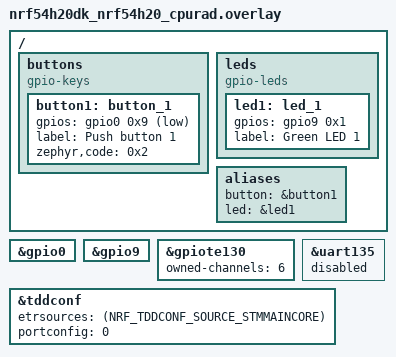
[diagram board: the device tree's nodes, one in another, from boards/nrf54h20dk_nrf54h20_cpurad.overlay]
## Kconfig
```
#
# Copyright (c) 2024 Nordic Semiconductor ASA
#
# SPDX-License-Identifier: LicenseRef-Nordic-5-Clause
#

menu "CoreMark sample"

config APP_MODE_FLASH_AND_RUN
	bool "Run CoreMark benchmark on start up" if \
		!(SOC_NRF54H20_CPUPPR)
	default y if SOC_NRF54H20_CPUPPR
	help
	  If enabled, CoreMark will start execution immediately after the CPU starts up.
	  It also disables LEDs and buttons.
	  Otherwise, it will wait for the button press.

endmenu

menu "Zephyr Kernel"
	source "Kconfig.zephyr"
endmenu
```

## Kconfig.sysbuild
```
#
# Copyright (c) 2024 Nordic Semiconductor ASA
#
# SPDX-License-Identifier: LicenseRef-Nordic-5-Clause
#

source "share/sysbuild/Kconfig"

config APP_CPUNET_RUN
	bool "Run the CoreMark benchmark on the network or radio core"
	depends on SUPPORT_NETCORE
	default y

config APP_CPUPPR_RUN
	bool "Run the CoreMark benchmark on the PPR core"
	depends on SUPPORT_PPRCORE
	default y
```

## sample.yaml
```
sample:
  name: CoreMark Benchmark
  description: CoreMark sample for the CPU performance evaluation.
               Sample runs the CoreMark benchmark that measures the CPU efficiency
               performing different algorithms like state machine, CRC calculation,
               matrix manipulation and list processing (find and sort).
tests:
  sample.benchmark.coremark:
    sysbuild: true
    build_only: true
    platform_allow:
      - nrf52840dk/nrf52840
      - nrf52833dk/nrf52833
      - nrf52dk/nrf52832
      - nrf5340dk/nrf5340/cpuapp
      - nrf54l15dk/nrf54l15/cpuapp
      - nrf54h20dk/nrf54h20/cpuapp
    integration_platforms:
      - nrf52840dk/nrf52840
      - nrf52833dk/nrf52833
      - nrf52dk/nrf52832
      - nrf5340dk/nrf5340/cpuapp
      - nrf54l15dk/nrf54l15/cpuapp
      - nrf54h20dk/nrf54h20/cpuapp
    tags: ci_build sysbuild ci_samples_benchmarks
  sample.benchmark.coremark.flash_and_run:
    sysbuild: true
    build_only: false
    platform_allow:
      - nrf52840dk/nrf52840
      - nrf52833dk/nrf52833
      - nrf52dk/nrf52832
      - nrf5340dk/nrf5340/cpuapp
      - nrf54l15dk/nrf54l15/cpuapp
      - nrf54h20dk/nrf54h20/cpuapp
    integration_platforms:
      - nrf52840dk/nrf52840
      - nrf52833dk/nrf52833
      - nrf52dk/nrf52832
      - nrf5340dk/nrf5340/cpuapp
      - nrf54l15dk/nrf54l15/cpuapp
      - nrf54h20dk/nrf54h20/cpuapp
    tags: ci_build sysbuild ci_samples_benchmarks
    harness: console
    harness_config:
      ordered: false
      regex:
        - "CoreMark started!"
        - "Correct operation validated."
      type: multi_line
    extra_args: FILE_SUFFIX=flash_and_run
  sample.benchmark.coremark.heap_memory:
    sysbuild: true
    build_only: true
    platform_allow:
      - nrf52840dk/nrf52840
      - nrf52833dk/nrf52833
      - nrf52dk/nrf52832
      - nrf5340dk/nrf5340/cpuapp
      - nrf54l15dk/nrf54l15/cpuapp
      - nrf54h20dk/nrf54h20/cpuapp
    integration_platforms:
      - nrf52840dk/nrf52840
      - nrf52833dk/nrf52833
      - nrf52dk/nrf52832
      - nrf5340dk/nrf5340/cpuapp
      - nrf54l15dk/nrf54l15/cpuapp
      - nrf54h20dk/nrf54h20/cpuapp
    tags: ci_build sysbuild ci_samples_benchmarks
    extra_args: FILE_SUFFIX=heap_memory
  sample.benchmark.coremark.static_memory:
    sysbuild: true
    build_only: true
    platform_allow:
      - nrf52840dk/nrf52840
      - nrf52833dk/nrf52833
      - nrf52dk/nrf52832
      - nrf5340dk/nrf5340/cpuapp
      - nrf54l15dk/nrf54l15/cpuapp
      - nrf54h20dk/nrf54h20/cpuapp
    integration_platforms:
      - nrf52840dk/nrf52840
      - nrf52833dk/nrf52833
      - nrf52dk/nrf52832
      - nrf5340dk/nrf5340/cpuapp
      - nrf54l15dk/nrf54l15/cpuapp
      - nrf54h20dk/nrf54h20/cpuapp
    tags: ci_build sysbuild ci_samples_benchmarks
    extra_args: FILE_SUFFIX=static_memory
  sample.benchmark.coremark.multiple_threads:
    sysbuild: true
    build_only: true
    platform_allow:
      - nrf52840dk/nrf52840
      - nrf52833dk/nrf52833
      - nrf52dk/nrf52832
      - nrf5340dk/nrf5340/cpuapp
      - nrf54l15dk/nrf54l15/cpuapp
      - nrf54h20dk/nrf54h20/cpuapp
    integration_platforms:
      - nrf52840dk/nrf52840
      - nrf52833dk/nrf52833
      - nrf52dk/nrf52832
      - nrf5340dk/nrf5340/cpuapp
      - nrf54l15dk/nrf54l15/cpuapp
      - nrf54h20dk/nrf54h20/cpuapp
    tags: ci_build sysbuild ci_samples_benchmarks
    extra_args: FILE_SUFFIX=multiple_threads
```

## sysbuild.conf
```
#
# Copyright (c) 2024 Nordic Semiconductor ASA
#
# SPDX-License-Identifier: LicenseRef-Nordic-5-Clause

SB_CONFIG_PARTITION_MANAGER=n
```

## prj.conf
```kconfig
#
# Copyright (c) 2024 Nordic Semiconductor ASA
#
# SPDX-License-Identifier: LicenseRef-Nordic-5-Clause

# Common coremark configuration
############################################################################
CONFIG_COREMARK=y

# Compiler options
CONFIG_COMPILER_OPT="-O3"

# Config results output
# The default logging level is set to the OFF level.
# Kernel error logging is enabled to notify the developer about system faults.
CONFIG_LOG=y
CONFIG_LOG_DEFAULT_LEVEL=0
CONFIG_KERNEL_LOG_LEVEL_ERR=y
CONFIG_CBPRINTF_FP_SUPPORT=y

CONFIG_GPIO=y

CONFIG_MAIN_THREAD_PRIORITY=-1

# Configuration variant:
# Memory allocation using the stack memory
# Single-threaded benchmark execution
# Benchmark execution on a button press
############################################################################

# Increse if number of threads increases.
CONFIG_MAIN_STACK_SIZE=4096
```

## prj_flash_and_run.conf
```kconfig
#
# Copyright (c) 2024 Nordic Semiconductor ASA
#
# SPDX-License-Identifier: LicenseRef-Nordic-5-Clause

# Common coremark configuration
############################################################################
CONFIG_COREMARK=y

# Compiler options
CONFIG_COMPILER_OPT="-O3"

# Config results output
# The default logging level is set to the OFF level.
# Kernel error logging is enabled to notify the developer about system faults.
CONFIG_LOG=y
CONFIG_LOG_DEFAULT_LEVEL=0
CONFIG_KERNEL_LOG_LEVEL_ERR=y
CONFIG_CBPRINTF_FP_SUPPORT=y

CONFIG_GPIO=y

CONFIG_MAIN_THREAD_PRIORITY=-1

# Configuration variant:
# Memory allocation using the stack memory
# Single-threaded benchmark execution
# Benchmark execution automatic after boot
############################################################################
CONFIG_APP_MODE_FLASH_AND_RUN=y

# Increse if number of threads increases.
CONFIG_MAIN_STACK_SIZE=4096
```

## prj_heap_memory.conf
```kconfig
#
# Copyright (c) 2024 Nordic Semiconductor ASA
#
# SPDX-License-Identifier: LicenseRef-Nordic-5-Clause

# Common coremark configuration
############################################################################
CONFIG_COREMARK=y

# Compiler options
CONFIG_COMPILER_OPT="-O3"

# Config results output
# The default logging level is set to the OFF level.
# Kernel error logging is enabled to notify the developer about system faults.
CONFIG_LOG=y
CONFIG_LOG_DEFAULT_LEVEL=0
CONFIG_KERNEL_LOG_LEVEL_ERR=y
CONFIG_CBPRINTF_FP_SUPPORT=y

CONFIG_GPIO=y

CONFIG_MAIN_THREAD_PRIORITY=-1

# Configuration variant:
# Memory allocation using the heap memory
# Single-threaded benchmark execution
# Benchmark execution on a button press
############################################################################

# Use heap memory allocation.
CONFIG_COREMARK_MEMORY_METHOD_MALLOC=y

# Adjust the heap memory size and main stack size.
# Increse if number of threads increases.
CONFIG_MAIN_STACK_SIZE=4096
CONFIG_HEAP_MEM_POOL_SIZE=4096
```

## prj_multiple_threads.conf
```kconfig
#
# Copyright (c) 2024 Nordic Semiconductor ASA
#
# SPDX-License-Identifier: LicenseRef-Nordic-5-Clause

# Common coremark configuration
############################################################################
CONFIG_COREMARK=y

# Compiler options
CONFIG_COMPILER_OPT="-O3"

# Config results output
# The default logging level is set to the OFF level.
# Kernel error logging is enabled to notify the developer about system faults.
CONFIG_LOG=y
CONFIG_LOG_DEFAULT_LEVEL=0
CONFIG_KERNEL_LOG_LEVEL_ERR=y
CONFIG_CBPRINTF_FP_SUPPORT=y

CONFIG_GPIO=y

CONFIG_MAIN_THREAD_PRIORITY=-1

# Configuration variant:
# Memory allocation using the stack memory
# Multi-threaded benchmark execution
# Benchmark execution on a button press
############################################################################

# Multi-threaded execution.
CONFIG_COREMARK_THREADS_NUMBER=4

# Increse if number of threads increases.
CONFIG_TIMESLICE_SIZE=10
CONFIG_MAIN_STACK_SIZE=10240
```

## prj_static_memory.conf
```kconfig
#
# Copyright (c) 2024 Nordic Semiconductor ASA
#
# SPDX-License-Identifier: LicenseRef-Nordic-5-Clause

# Common coremark configuration
############################################################################
CONFIG_COREMARK=y

# Compiler options
CONFIG_COMPILER_OPT="-O3"

# Config results output
# The default logging level is set to the OFF level.
# Kernel error logging is enabled to notify the developer about system faults.
CONFIG_LOG=y
CONFIG_LOG_DEFAULT_LEVEL=0
CONFIG_KERNEL_LOG_LEVEL_ERR=y
CONFIG_CBPRINTF_FP_SUPPORT=y

CONFIG_GPIO=y

CONFIG_MAIN_THREAD_PRIORITY=-1

# Configuration variant:
# Memory allocation using the static memory
# Single-threaded benchmark execution
# Benchmark execution on a button press
############################################################################

# Use static memory allocation.
CONFIG_COREMARK_MEMORY_METHOD_STATIC=y

# Increse if number of threads increases.
CONFIG_MAIN_STACK_SIZE=4096
```

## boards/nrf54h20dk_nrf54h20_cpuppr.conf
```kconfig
#
# Copyright (c) 2024 Nordic Semiconductor ASA
#
# SPDX-License-Identifier: LicenseRef-Nordic-5-Clause

CONFIG_COREMARK_ITERATIONS=500

# Disable the UART console Kconfig to make Kconfig configuration with the DTS configuration.
CONFIG_UART_CONSOLE=n

# Kconfigs required for the STM standalone logging, imported from the nordic-log-stm snippet.
CONFIG_TEST_LOGGING_DEFAULTS=n
CONFIG_LOG_FRONTEND=y
CONFIG_LOG_FRONTEND_ONLY=y
CONFIG_LOG_FRONTEND_STMESP=y
CONFIG_LOG_FRONTEND_STMESP_FSC=y

# Disable the NCS boot banner - the application core is responsible for printing the boot banner.
CONFIG_NCS_BOOT_BANNER=n
CONFIG_BOOT_BANNER=n
```

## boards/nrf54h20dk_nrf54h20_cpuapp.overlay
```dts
/*
 * Copyright (c) 2024 Nordic Semiconductor ASA
 *
 * SPDX-License-Identifier: LicenseRef-Nordic-5-Clause
 */

 #include "app_aliases_common.overlay"

/ {
	chosen {
		zephyr,sram = &cpuapp_ram0;
	};

	aliases {
		/delete-property/ led1;
		/delete-property/ sw1;
	};
};

/delete-node/ &button1;
/delete-node/ &led1;

&button0 {
	label = "Push button 0";
};

&gpiote130 {
	/* Select the only free channel. */
	owned-channels = <7>;
	status = "okay";
};

/* DTS nodes required to run the cpuppr target. */
&cpuppr_vpr {
	status = "okay";
};

&cpuppr_ram3x_region {
	status = "okay";
};

/* DTS nodes required for the STM standalone logging, imported from the nordic-log-stm snippet. */
&tbm {
	status = "okay";
};

&tddconf {
	status = "okay";
	etrsources = <(NRF_TDDCONF_SOURCE_STMMAINCORE | NRF_TDDCONF_SOURCE_STMPPR)>;
	portconfig = <0>;
};
```

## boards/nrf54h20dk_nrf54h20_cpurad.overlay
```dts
/*
 * Copyright (c) 2024 Nordic Semiconductor ASA
 *
 * SPDX-License-Identifier: LicenseRef-Nordic-5-Clause
 */

/ {
	buttons {
		compatible = "gpio-keys";
		button1: button_1 {
			gpios = < &gpio0 0x9 0x11 >;
			label = "Push button 1";
			zephyr,code = < 0x2 >;
		};
	};

	leds {
		compatible = "gpio-leds";
		led1: led_1 {
			gpios = < &gpio9 0x1 0x0 >;
			label = "Green LED 1";
		};
	};

	aliases {
		button = &button1;
		led = &led1;
	};
 };

&gpio0 {
	status = "okay";
};

&gpio9 {
	status = "okay";
};

&gpiote130 {
	owned-channels = <6>;
	status = "okay";
};

/* Disable the default UART node for the radio core, as logs are forwarded
 * with STM and the application core UART. This setting also prevents access
 * issues to the same UART instance from two or more different cores.
 */
&uart135 {
	status = "disabled";
};

/* DTS nodes required for the STM standalone logging, imported from the nordic-log-stm snippet. */
&tddconf {
	status = "okay";
	etrsources = <(NRF_TDDCONF_SOURCE_STMMAINCORE)>;
	portconfig = <0>;
};
```

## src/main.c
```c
/*
 * Copyright (c) 2024 Nordic Semiconductor ASA
 *
 * SPDX-License-Identifier: LicenseRef-Nordic-5-Clause
 */

#include <zephyr/init.h>
#include <zephyr/kernel.h>
#include <zephyr/logging/log.h>
#include <zephyr/drivers/gpio.h>
#include <zephyr/drivers/misc/coresight/nrf_etr.h>
#include <system_nrf.h>

#include "coremark_zephyr.h"

LOG_MODULE_REGISTER(app, LOG_LEVEL_INF);

#ifndef CONFIG_APP_MODE_FLASH_AND_RUN
/*
 * Get button configuration from the devicetree. This is mandatory.
 */
#define BUTTON_NODE             DT_ALIAS(button)
#define LED_NODE                DT_ALIAS(led)

#if !DT_NODE_HAS_STATUS(BUTTON_NODE, okay)
	#error "Unsupported board: /"button/" alias is not defined."
#endif

#if !DT_NODE_HAS_STATUS(LED_NODE, okay)
	#error "Unsupported board: /"led/" alias is not defined."
#endif

#define BUTTON_LABEL            DT_PROP(DT_ALIAS(button), label)
#define LED_ON()                (void)gpio_pin_set_dt(&status_led, 1)
#define LED_OFF()               (void)gpio_pin_set_dt(&status_led, 0)

static const struct gpio_dt_spec start_button = GPIO_DT_SPEC_GET(BUTTON_NODE, gpios);
static const struct gpio_dt_spec status_led = GPIO_DT_SPEC_GET(LED_NODE, gpios);

#else

#define BUTTON_LABEL            "Reset"
#define LED_ON()
#define LED_OFF()

static const struct gpio_dt_spec start_button;
static const struct gpio_dt_spec status_led;

#endif

static K_SEM_DEFINE(start_coremark, 0, 1);
static atomic_t coremark_in_progress;

static void logging_mode_multi_domain_blocked_state_indicate(void)
{
	if (!IS_ENABLED(CONFIG_NRF_ETR)) {
		return;
	}

	LOG_INF("Logging is blocked for all cores until this core finishes the CoreMark "
		"benchmark\n");

	/* The wait time is necessary to include the log in the ETR flush operation. The logging
	 * frontend submits the log to the STM port (STMESP), which STM processes and directs the
	 * generated logging stream to the STM sink - ETR. The log should be available in the ETR
	 * peripheral after the sleep operation.
	 */
	k_sleep(K_MSEC(100));

	/* Flush logs from the ETR and direct them to UART. */
	nrf_etr_flush();
}

static int logging_mode_indicate(void)
{
	/* Enforce synchronous logging as the sample doesn't flush logs. */
	BUILD_ASSERT(IS_ENABLED(CONFIG_LOG_MODE_MINIMAL) ||
		     IS_ENABLED(CONFIG_LOG_MODE_IMMEDIATE) ||
		     IS_ENABLED(CONFIG_LOG_FRONTEND_ONLY),
		     "Logs should be processed synchronously to avoid negative impact on the "
		     "benchamrk performance");

	/* Standard logging mode */
	if (IS_ENABLED(CONFIG_LOG_MODE_MINIMAL) || IS_ENABLED(CONFIG_LOG_MODE_IMMEDIATE)) {
		LOG_INF("Standard logging mode\n");

		return 0;
	}

	/* Multi-domain logging mode */
	if (IS_ENABLED(CONFIG_LOG_FRONTEND_ONLY) || IS_ENABLED(CONFIG_LOG_FRONTEND_STMESP)) {
		/* Only the core responsible for moving the logs from the STM sink to UART
		 * indicates the logging mode.
		 */
		if (IS_ENABLED(CONFIG_NRF_ETR)) {
			LOG_INF("Multi-domain logging mode");
			LOG_INF("This core is used to output logs from all cores to terminal "
				"over UART\n");
		}

		return 0;
	}

	/* This part should never be executed. */
	k_panic();

	return 0;
}

SYS_INIT(logging_mode_indicate, APPLICATION, CONFIG_APPLICATION_INIT_PRIORITY);

static void button_pressed(const struct device *dev, struct gpio_callback *cb, uint32_t pins)
{
	if (gpio_pin_get_dt(&start_button) && atomic_cas(&coremark_in_progress, false, true)) {
		LOG_INF("%s pressed!", BUTTON_LABEL);
		k_sem_give(&start_coremark);
	}
}

static int led_init(void)
{
	int ret;

	if (!device_is_ready(status_led.port)) {
		LOG_ERR("Error: led device %s is not ready",
			status_led.port->name);
		return -ENODEV;
	}

	ret = gpio_pin_configure_dt(&status_led, GPIO_OUTPUT);
	if (ret != 0) {
		LOG_ERR("Error %d: failed to configure %s pin %d",
			ret, status_led.port->name, status_led.pin);
		return ret;
	}

	LED_OFF();

	return ret;
}

static int button_init(void)
{
	int ret;
	static struct gpio_callback button_cb_data;

	if (!device_is_ready(start_button.port)) {
		LOG_ERR("Error: button1 device %s is not ready",
			start_button.port->name);
		return -ENODEV;
	}

	ret = gpio_pin_configure_dt(&start_button, GPIO_INPUT);
	if (ret != 0) {
		LOG_ERR("Error %d: failed to configure %s pin %d",
			ret, start_button.port->name, start_button.pin);
		return ret;
	}

	ret = gpio_pin_interrupt_configure_dt(&start_button, GPIO_INT_EDGE_TO_ACTIVE);
	if (ret != 0) {
		LOG_ERR("Error %d: failed to configure interrupt on %s pin %d",
			ret, start_button.port->name, start_button.pin);
		return ret;
	}

	(void) gpio_init_callback(&button_cb_data, button_pressed, BIT(start_button.pin));
	(void) gpio_add_callback(start_button.port, &button_cb_data);

	return ret;
}

int main(void)
{
	LOG_INF("CoreMark sample for %s", CONFIG_BOARD_TARGET);

	if (IS_ENABLED(CONFIG_APP_MODE_FLASH_AND_RUN)) {
		(void)atomic_set(&coremark_in_progress, true);
		k_sem_give(&start_coremark);
	} else if (!IS_ENABLED(CONFIG_APP_MODE_FLASH_AND_RUN)) {
		if (led_init()) {
			k_panic();
		}
		if (button_init()) {
			k_panic();
		}

		LOG_INF("Press %s to start the test ...\n",  BUTTON_LABEL);
	}

	while (true) {
		k_sem_take(&start_coremark, K_FOREVER);
		LOG_INF("CoreMark started! "
			"CPU FREQ: %d Hz, threads: %d, data size: %d; iterations: %d\n",
			SystemCoreClock,
			CONFIG_COREMARK_THREADS_NUMBER,
			CONFIG_COREMARK_DATA_SIZE,
			CONFIG_COREMARK_ITERATIONS);

		logging_mode_multi_domain_blocked_state_indicate();

		LED_ON();
		coremark_run();
		LED_OFF();

		if (IS_ENABLED(CONFIG_APP_MODE_FLASH_AND_RUN)) {
			LOG_INF("CoreMark finished! Press the reset button to restart...\n");
		} else {
			LOG_INF("CoreMark finished! Press %s to restart ...\n", BUTTON_LABEL);
		}

		(void)atomic_set(&coremark_in_progress, false);
	};

	return 0;
}
```
